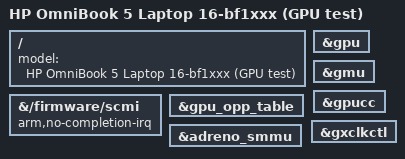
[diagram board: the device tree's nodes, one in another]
// SPDX-License-Identifier: BSD-3-Clause
/*
 * HP OmniBook 5 16-bf1xxx, GPU test device tree: the full device tree with
 * the Adreno X2-85 GPU turned on, plus the SCMI polling fix for CPU
 * frequency scaling. Kept separate from the full device tree, whose
 * display is known to work, until both are proven here.
 *
 * GPU: Windows binds this GPU as "Adreno X2-85" (ACPI QCOM0FF5), the chip
 * glymur.dtsi describes (qcom,adreno-44070001, GMU x285.1). As on the
 * upstream Glymur laptops (ASUS Zenbook A16, HP EliteBook X G2q, HP
 * OmniBook Ultra 14), no zap shader is declared: the driver falls back to
 * SECVID_TRUST_CNTL. It needs qcom/gen80100_sqe.fw and gen80100_gmu.bin
 * from linux-firmware. The driver picks the OPPs from the chip's speed-bin
 * fuse; for this first bring-up the three OPPs above 1.35 GHz (the ceiling
 * every bin supports) are removed as well.
 *
 * SCMI: the CPUCP firmware writes SCMI replies without ringing the mailbox
 * doorbell, so interrupt-mode transfers time out (lab run 1). This is
 * "arm64: dts: qcom: glymur: use polling mode for SCMI transfers" (Jesse
 * Casco, 2026-08-08), applied at board level. scmi-cpufreq is still a
 * module that nothing loads automatically.
 */
/dts-v1/;

#include "mahua-hp-omnibook-5-bf1xxx.dts"

/ {
	model = "HP OmniBook 5 Laptop 16-bf1xxx (GPU test)";
};

&{/firmware/scmi} {
	arm,no-completion-irq;
};

&gpu {
	status = "okay";
};

&gpu_opp_table {
	/delete-node/ opp-1550000000;
	/delete-node/ opp-1700000000;
	/delete-node/ opp-1850000000;
};

&gmu {
	status = "okay";
};

&gpucc {
	status = "okay";
};

&gxclkctl {
	status = "okay";
};

&adreno_smmu {
	status = "okay";
};
